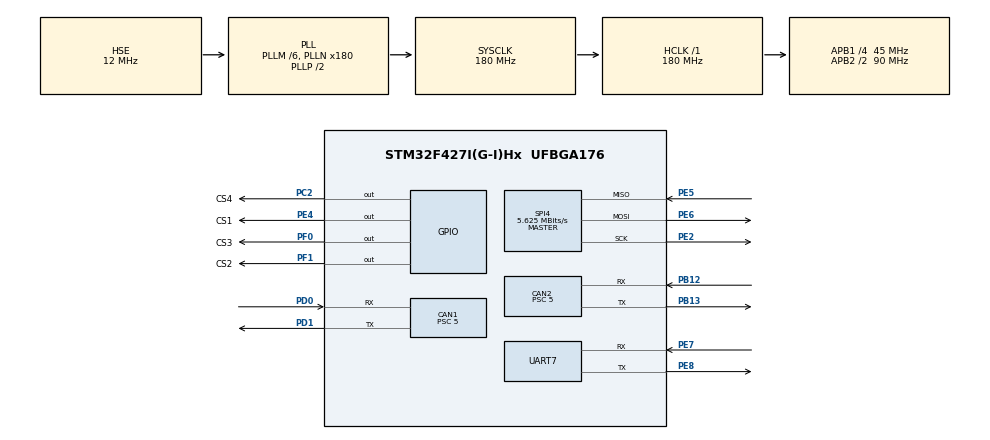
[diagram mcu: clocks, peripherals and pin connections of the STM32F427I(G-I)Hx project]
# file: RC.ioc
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CAN1.ABOM=ENABLE
CAN1.BS1=CAN_BS1_3TQ
CAN1.BS2=CAN_BS2_5TQ
CAN1.CalculateBaudRate=1000000
CAN1.CalculateTimeBit=1000
CAN1.CalculateTimeQuantum=111.11111111111111
CAN1.Mode=CAN_MODE_NORMAL
CAN1.NART=ENABLE
CAN1.Prescaler=5
CAN2.ABOM=DISABLE
CAN2.BS1=CAN_BS1_3TQ
CAN2.BS2=CAN_BS2_5TQ
CAN2.CalculateBaudRate=1000000
CAN2.CalculateTimeBit=1000
CAN2.CalculateTimeQuantum=111.11111111111111
CAN2.NART=DISABLE
CAN2.Prescaler=5
FREERTOS.Tasks01=defaultTask,0,128,StartDefaultTask,Default,NULL,Dynamic,NULL,NULL
FREERTOS.configENABLE_FPU=1
Mcu.Family=STM32F4
Mcu.Name=STM32F427I(G-I)Hx
Mcu.Package=UFBGA176
NVIC.CAN1_RX0_IRQn=true\:5\:0\:false\:false\:true\:true\:true\:true\:true
NVIC.CAN2_RX0_IRQn=true\:5\:0\:false\:false\:true\:true\:true\:true\:true
NVIC.PriorityGroup=NVIC_PRIORITYGROUP_4
NVIC.SPI4_IRQn=true\:5\:0\:false\:false\:true\:true\:true\:true\:true
NVIC.TIM8_UP_TIM13_IRQn=true\:15\:0\:false\:false\:true\:false\:false\:true\:true
NVIC.TimeBase=TIM8_UP_TIM13_IRQn
NVIC.TimeBaseIP=TIM13
PA13.Mode=Serial_Wire
PA13.Signal=SYS_JTMS-SWDIO
PA14.Mode=Serial_Wire
PA14.Signal=SYS_JTCK-SWCLK
PB12.Mode=CAN_Activate
PB12.Signal=CAN2_RX
PB13.Mode=CAN_Activate
PB13.Signal=CAN2_TX
PC2.GPIO_Label=CS4
PC2.GPIO_PuPd=GPIO_PULLUP
PC2.Signal=GPIO_Output
PD0.Mode=CAN_Activate
PD0.Signal=CAN1_RX
PD1.Mode=CAN_Activate
PD1.Signal=CAN1_TX
PE2.Mode=Full_Duplex_Master
PE2.Signal=SPI4_SCK
PE4.GPIO_Label=CS1
PE4.GPIO_PuPd=GPIO_PULLUP
PE4.Signal=GPIO_Output
PE5.Mode=Full_Duplex_Master
PE5.Signal=SPI4_MISO
PE6.Mode=Full_Duplex_Master
PE6.Signal=SPI4_MOSI
PE7.Mode=Asynchronous
PE7.Signal=UART7_RX
PE8.Mode=Asynchronous
PE8.Signal=UART7_TX
PF0.GPIO_Label=CS3
PF0.GPIO_PuPd=GPIO_PULLUP
PF0.Signal=GPIO_Output
PF1.GPIO_Label=CS2
PF1.GPIO_PuPd=GPIO_PULLUP
PF1.Signal=GPIO_Output
PH0/OSC_IN.Mode=HSE-External-Oscillator
PH0/OSC_IN.Signal=RCC_OSC_IN
PH1/OSC_OUT.Mode=HSE-External-Oscillator
PH1/OSC_OUT.Signal=RCC_OSC_OUT
ProjectManager.HeapSize=0x4000
ProjectManager.StackSize=0x400
ProjectManager.TargetToolchain=MDK-ARM V5.32
RCC.48MHZClocksFreq_Value=90000000
RCC.AHBFreq_Value=180000000
RCC.APB1CLKDivider=RCC_HCLK_DIV4
RCC.APB1Freq_Value=45000000
RCC.APB1TimFreq_Value=90000000
RCC.APB2CLKDivider=RCC_HCLK_DIV2
RCC.APB2Freq_Value=90000000
RCC.APB2TimFreq_Value=180000000
RCC.CortexFreq_Value=180000000
RCC.HCLKFreq_Value=180000000
RCC.HSE_VALUE=12000000
RCC.HSI_VALUE=16000000
RCC.LSE_VALUE=32768
RCC.PLLM=6
RCC.PLLN=180
RCC.PLLSourceVirtual=RCC_PLLSOURCE_HSE
RCC.SYSCLKFreq_VALUE=180000000
RCC.SYSCLKSource=RCC_SYSCLKSOURCE_PLLCLK
RCC.VCOOutputFreq_Value=360000000
SPI4.BaudRatePrescaler=SPI_BAUDRATEPRESCALER_16
SPI4.CLKPhase=SPI_PHASE_2EDGE
SPI4.CalculateBaudRate=5.625 MBits/s
SPI4.DataSize=SPI_DATASIZE_16BIT
SPI4.Direction=SPI_DIRECTION_2LINES
SPI4.Mode=SPI_MODE_MASTER
SPI4.VirtualType=VM_MASTER
STMicroelectronics.X-CUBE-ALGOBUILD.1.4.0.LibraryCcDSPOoLibraryJjDSPOoLibrary=true
UART7.VirtualMode=Asynchronous
VP_FREERTOS_VS_CMSIS_V1.Mode=CMSIS_V1
VP_STMicroelectronics.X-CUBE-ALGOBUILD_VS_DSPOoLibraryJjLibrary_1.4.0_1.4.0.Mode=DSPOoLibraryJjLibrary
VP_SYS_VS_tim13.Mode=TIM13
board=custom

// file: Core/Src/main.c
/* USER CODE BEGIN Header */
/**
 ******************************************************************************
 * @file           : main.c
 * @brief          : Main program body
 ******************************************************************************
 * @attention
 *
 * Copyright (c) 2024 STMicroelectronics.
 * All rights reserved.
 *
 * This software is licensed under terms that can be found in the LICENSE file
 * in the root directory of this software component.
 * If no LICENSE file comes with this software, it is provided AS-IS.
 *
 ******************************************************************************
 */
/* USER CODE END Header */
#include "main.h"
#include "cmsis_os.h"

/* USER CODE BEGIN Includes */
#include "maincpp.h"
/* USER CODE END Includes */

CAN_HandleTypeDef hcan1;
CAN_HandleTypeDef hcan2;

SPI_HandleTypeDef hspi4;

UART_HandleTypeDef huart7;

osThreadId defaultTaskHandle;

void SystemClock_Config(void);
static void MX_GPIO_Init(void);
static void MX_CAN1_Init(void);
static void MX_CAN2_Init(void);
static void MX_UART7_Init(void);
static void MX_SPI4_Init(void);
void StartDefaultTask(void const * argument);

int main(void)
{

  /* MCU Configuration--------------------------------------------------------*/

  /* Reset of all peripherals, Initializes the Flash interface and the Systick. */
  HAL_Init();

  /* Configure the system clock */
  SystemClock_Config();

  /* Initialize all configured peripherals */
  MX_GPIO_Init();
  MX_CAN1_Init();
  MX_CAN2_Init();
  MX_UART7_Init();
  MX_SPI4_Init();
  /* USER CODE BEGIN 2 */
  main_cpp();
  /* USER CODE END 2 */

  /* Create the thread(s) */
  /* definition and creation of defaultTask */
  osThreadDef(defaultTask, StartDefaultTask, osPriorityNormal, 0, 128);
  defaultTaskHandle = osThreadCreate(osThread(defaultTask), NULL);

  /* Start scheduler */
  osKernelStart();

  /* We should never get here as control is now taken by the scheduler */

  /* Infinite loop */
  while (1)
  {

  }
}

void SystemClock_Config(void)
{
  RCC_OscInitTypeDef RCC_OscInitStruct = {0};
  RCC_ClkInitTypeDef RCC_ClkInitStruct = {0};

  /** Configure the main internal regulator output voltage
  */
  __HAL_RCC_PWR_CLK_ENABLE();
  __HAL_PWR_VOLTAGESCALING_CONFIG(PWR_REGULATOR_VOLTAGE_SCALE1);

  /** Initializes the RCC Oscillators according to the specified parameters
  * in the RCC_OscInitTypeDef structure.
  */
  RCC_OscInitStruct.OscillatorType = RCC_OSCILLATORTYPE_HSE;
  RCC_OscInitStruct.HSEState = RCC_HSE_ON;
  RCC_OscInitStruct.PLL.PLLState = RCC_PLL_ON;
  RCC_OscInitStruct.PLL.PLLSource = RCC_PLLSOURCE_HSE;
  RCC_OscInitStruct.PLL.PLLM = 6;
  RCC_OscInitStruct.PLL.PLLN = 180;
  RCC_OscInitStruct.PLL.PLLP = RCC_PLLP_DIV2;
  RCC_OscInitStruct.PLL.PLLQ = 4;
  if (HAL_RCC_OscConfig(&RCC_OscInitStruct) != HAL_OK)
  {
    Error_Handler();
  }

  /** Activate the Over-Drive mode
  */
  if (HAL_PWREx_EnableOverDrive() != HAL_OK)
  {
    Error_Handler();
  }

  /** Initializes the CPU, AHB and APB buses clocks
  */
  RCC_ClkInitStruct.ClockType = RCC_CLOCKTYPE_HCLK|RCC_CLOCKTYPE_SYSCLK
                              |RCC_CLOCKTYPE_PCLK1|RCC_CLOCKTYPE_PCLK2;
  RCC_ClkInitStruct.SYSCLKSource = RCC_SYSCLKSOURCE_PLLCLK;
  RCC_ClkInitStruct.AHBCLKDivider = RCC_SYSCLK_DIV1;
  RCC_ClkInitStruct.APB1CLKDivider = RCC_HCLK_DIV4;
  RCC_ClkInitStruct.APB2CLKDivider = RCC_HCLK_DIV2;

  if (HAL_RCC_ClockConfig(&RCC_ClkInitStruct, FLASH_LATENCY_5) != HAL_OK)
  {
    Error_Handler();
  }
}

static void MX_CAN1_Init(void)
{

  hcan1.Instance = CAN1;
  hcan1.Init.Prescaler = 5;
  hcan1.Init.Mode = CAN_MODE_NORMAL;
  hcan1.Init.SyncJumpWidth = CAN_SJW_1TQ;
  hcan1.Init.TimeSeg1 = CAN_BS1_3TQ;
  hcan1.Init.TimeSeg2 = CAN_BS2_5TQ;
  hcan1.Init.TimeTriggeredMode = DISABLE;
  hcan1.Init.AutoBusOff = ENABLE;
  hcan1.Init.AutoWakeUp = DISABLE;
  hcan1.Init.AutoRetransmission = ENABLE;
  hcan1.Init.ReceiveFifoLocked = DISABLE;
  hcan1.Init.TransmitFifoPriority = DISABLE;
  if (HAL_CAN_Init(&hcan1) != HAL_OK)
  {
    Error_Handler();
  }

}

static void MX_CAN2_Init(void)
{

  hcan2.Instance = CAN2;
  hcan2.Init.Prescaler = 5;
  hcan2.Init.Mode = CAN_MODE_NORMAL;
  hcan2.Init.SyncJumpWidth = CAN_SJW_1TQ;
  hcan2.Init.TimeSeg1 = CAN_BS1_3TQ;
  hcan2.Init.TimeSeg2 = CAN_BS2_5TQ;
  hcan2.Init.TimeTriggeredMode = DISABLE;
  hcan2.Init.AutoBusOff = DISABLE;
  hcan2.Init.AutoWakeUp = DISABLE;
  hcan2.Init.AutoRetransmission = DISABLE;
  hcan2.Init.ReceiveFifoLocked = DISABLE;
  hcan2.Init.TransmitFifoPriority = DISABLE;
  if (HAL_CAN_Init(&hcan2) != HAL_OK)
  {
    Error_Handler();
  }

}

static void MX_SPI4_Init(void)
{

  /* SPI4 parameter configuration*/
  hspi4.Instance = SPI4;
  hspi4.Init.Mode = SPI_MODE_MASTER;
  hspi4.Init.Direction = SPI_DIRECTION_2LINES;
  hspi4.Init.DataSize = SPI_DATASIZE_16BIT;
  hspi4.Init.CLKPolarity = SPI_POLARITY_LOW;
  hspi4.Init.CLKPhase = SPI_PHASE_2EDGE;
  hspi4.Init.NSS = SPI_NSS_SOFT;
  hspi4.Init.BaudRatePrescaler = SPI_BAUDRATEPRESCALER_16;
  hspi4.Init.FirstBit = SPI_FIRSTBIT_MSB;
  hspi4.Init.TIMode = SPI_TIMODE_DISABLE;
  hspi4.Init.CRCCalculation = SPI_CRCCALCULATION_DISABLE;
  hspi4.Init.CRCPolynomial = 10;
  if (HAL_SPI_Init(&hspi4) != HAL_OK)
  {
    Error_Handler();
  }

}

static void MX_UART7_Init(void)
{

  huart7.Instance = UART7;
  huart7.Init.BaudRate = 115200;
  huart7.Init.WordLength = UART_WORDLENGTH_8B;
  huart7.Init.StopBits = UART_STOPBITS_1;
  huart7.Init.Parity = UART_PARITY_NONE;
  huart7.Init.Mode = UART_MODE_TX_RX;
  huart7.Init.HwFlowCtl = UART_HWCONTROL_NONE;
  huart7.Init.OverSampling = UART_OVERSAMPLING_16;
  if (HAL_UART_Init(&huart7) != HAL_OK)
  {
    Error_Handler();
  }

}

static void MX_GPIO_Init(void)
{
  GPIO_InitTypeDef GPIO_InitStruct = {0};

  /* GPIO Ports Clock Enable */
  __HAL_RCC_GPIOE_CLK_ENABLE();
  __HAL_RCC_GPIOA_CLK_ENABLE();
  __HAL_RCC_GPIOD_CLK_ENABLE();
  __HAL_RCC_GPIOF_CLK_ENABLE();
  __HAL_RCC_GPIOH_CLK_ENABLE();
  __HAL_RCC_GPIOC_CLK_ENABLE();
  __HAL_RCC_GPIOB_CLK_ENABLE();

  /*Configure GPIO pin Output Level */
  HAL_GPIO_WritePin(CS1_GPIO_Port, CS1_Pin, GPIO_PIN_RESET);

  /*Configure GPIO pin Output Level */
  HAL_GPIO_WritePin(GPIOF, CS3_Pin|CS2_Pin, GPIO_PIN_RESET);

  /*Configure GPIO pin Output Level */
  HAL_GPIO_WritePin(CS4_GPIO_Port, CS4_Pin, GPIO_PIN_RESET);

  /*Configure GPIO pin : CS1_Pin */
  GPIO_InitStruct.Pin = CS1_Pin;
  GPIO_InitStruct.Mode = GPIO_MODE_OUTPUT_PP;
  GPIO_InitStruct.Pull = GPIO_PULLUP;
  GPIO_InitStruct.Speed = GPIO_SPEED_FREQ_LOW;
  HAL_GPIO_Init(CS1_GPIO_Port, &GPIO_InitStruct);

  /*Configure GPIO pins : CS3_Pin CS2_Pin */
  GPIO_InitStruct.Pin = CS3_Pin|CS2_Pin;
  GPIO_InitStruct.Mode = GPIO_MODE_OUTPUT_PP;
  GPIO_InitStruct.Pull = GPIO_PULLUP;
  GPIO_InitStruct.Speed = GPIO_SPEED_FREQ_LOW;
  HAL_GPIO_Init(GPIOF, &GPIO_InitStruct);

  /*Configure GPIO pin : CS4_Pin */
  GPIO_InitStruct.Pin = CS4_Pin;
  GPIO_InitStruct.Mode = GPIO_MODE_OUTPUT_PP;
  GPIO_InitStruct.Pull = GPIO_PULLUP;
  GPIO_InitStruct.Speed = GPIO_SPEED_FREQ_LOW;
  HAL_GPIO_Init(CS4_GPIO_Port, &GPIO_InitStruct);

}

void StartDefaultTask(void const * argument)
{
  for(;;)
  {
    osDelay(1);
  }
}

void HAL_TIM_PeriodElapsedCallback(TIM_HandleTypeDef *htim)
{
  if (htim->Instance == TIM13) {
    HAL_IncTick();
  }
}

void Error_Handler(void)
{
  __disable_irq();
  while (1)
  {
  }
}
